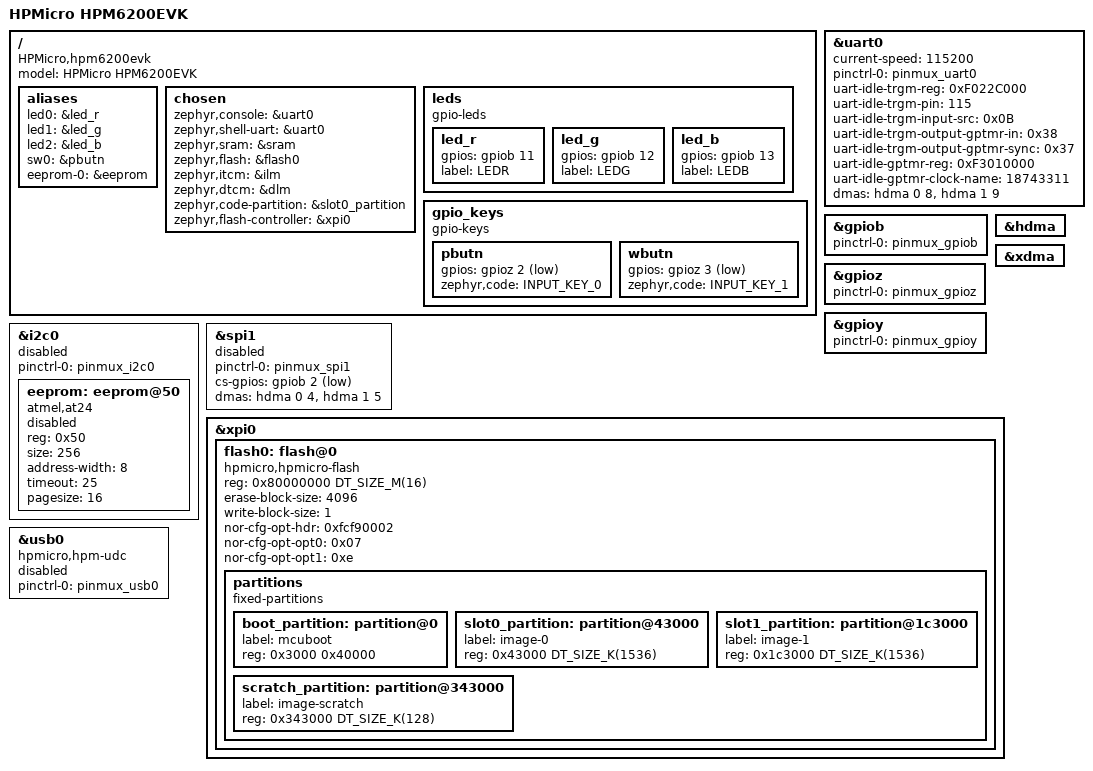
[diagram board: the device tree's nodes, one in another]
/*
 * Copyright 2025 HPMicro
 * SPDX-License-Identifier: Apache-2.0
 */

/dts-v1/;

#include <hpmicro/hpm6280.dtsi>
#include "hpm6200evk-pinctrl.dtsi"
#include <zephyr/dt-bindings/input/input-event-codes.h>

/ {
	model = "HPMicro HPM6200EVK";
	compatible = "HPMicro,hpm6200evk";

	aliases {
		led0 = &led_r;
		led1 = &led_g;
		led2 = &led_b;
		sw0 = &pbutn;
		eeprom-0 = &eeprom;
	};

	chosen {
		zephyr,console = &uart0;
		zephyr,shell-uart = &uart0;
		zephyr,sram = &sram;
		zephyr,flash = &flash0;
		zephyr,itcm = &ilm;
		zephyr,dtcm = &dlm;
		zephyr,code-partition = &slot0_partition;
		zephyr,flash-controller = &xpi0;
	};

	leds {
		compatible = "gpio-leds";
		led_r: led_r {
			gpios = <&gpiob 11 (GPIO_PULL_DOWN | GPIO_ACTIVE_HIGH)>;
			label = "LEDR";
		};
		led_g: led_g {
			gpios = <&gpiob 12 (GPIO_PULL_DOWN | GPIO_ACTIVE_HIGH)>;
			label = "LEDG";
		};
		led_b: led_b {
			gpios = <&gpiob 13 (GPIO_PULL_DOWN | GPIO_ACTIVE_HIGH)>;
			label = "LEDB";
		};
	};

	gpio_keys {
		compatible = "gpio-keys";
		pbutn: pbutn {
			gpios = <&gpioz 2 (GPIO_PULL_UP | GPIO_ACTIVE_LOW)>;
			zephyr,code = <INPUT_KEY_0>;
		};
		wbutn: wbutn {
			gpios = <&gpioz 3 (GPIO_PULL_UP | GPIO_ACTIVE_LOW)>;
			zephyr,code = <INPUT_KEY_1>;
		};
	};
};

&uart0 {
	status = "okay";
	current-speed = <115200>;
	pinctrl-0 = <&pinmux_uart0>;
	pinctrl-names = "default";
	uart-idle-trgm-reg = <0xF022C000>;
	uart-idle-trgm-pin = <115>;
	uart-idle-trgm-input-src = <0x0B>;
	uart-idle-trgm-output-gptmr-in = <0x38>;
	uart-idle-trgm-output-gptmr-sync = <0x37>;
	uart-idle-gptmr-reg = <0xF3010000>;
	uart-idle-gptmr-clock-name = <18743311>;
	dmas = <&hdma 0 8>, <&hdma 1 9>;
	dma-names = "rx", "tx";
};

&gpiob {
	pinctrl-0 = <&pinmux_gpiob>;
	pinctrl-names = "default";
	status = "okay";
};

&gpioz {
	pinctrl-0 = <&pinmux_gpioz>;
	pinctrl-names = "default";
	status = "okay";
};

&gpioy {
	pinctrl-0 = <&pinmux_gpioy>;
	pinctrl-names = "default";
	status = "okay";
};

&i2c0 {
	status = "disabled";
	pinctrl-0 = <&pinmux_i2c0>;
	pinctrl-names = "default";

	eeprom: eeprom@50 {
		compatible = "atmel,at24";
		status = "disabled";
		reg = <0x50>;
		size = <256>;
		address-width = <8>;
		timeout = <25>;
		pagesize = <16>;
	};
};

&spi1 {
	status = "disabled";
	pinctrl-0 = <&pinmux_spi1>;
	pinctrl-names = "default";
	cs-gpios = <&gpiob 2 GPIO_ACTIVE_LOW>;
	/* HDMA channels 0 and 1, muxed to SPI1 RX and TX */
	dmas = <&hdma 0 4>, <&hdma 1 5>;
	dma-names = "rx", "tx";
};

&hdma {
	status = "okay";
};

&xdma {
	status = "okay";
};

&xpi0 {
	status = "okay";
	flash0: flash@0 {
		compatible = "hpmicro,hpmicro-flash", "soc-nv-flash";
		reg = <0x80000000 DT_SIZE_M(16)>;
		status = "okay";
		erase-block-size = <4096>;
		write-block-size = <1>;
		nor-cfg-opt-hdr = <0xfcf90002>;
		nor-cfg-opt-opt0 = <0x07>;
		nor-cfg-opt-opt1 = <0xe>;

		partitions {
			compatible = "fixed-partitions";
			#address-cells = <1>;
			#size-cells = <1>;

			boot_partition: partition@0 {
				label = "mcuboot";
				reg = <0x3000 0x40000>;
			};

			slot0_partition: partition@43000 {
				label = "image-0";
				reg = <0x43000 DT_SIZE_K(1536)>;
			};

			slot1_partition: partition@1c3000 {
				label = "image-1";
				reg = <0x1c3000 DT_SIZE_K(1536)>;
			};

			scratch_partition: partition@343000 {
				label = "image-scratch";
				reg = <0x343000 DT_SIZE_K(128)>;
			};
		};
	};
};

&usb0 {
	pinctrl-0 = <&pinmux_usb0>;
	pinctrl-names = "default";
};

zephyr_udc0: &usb0 {
	compatible = "hpmicro,hpm-udc";
	status = "disabled";
};
